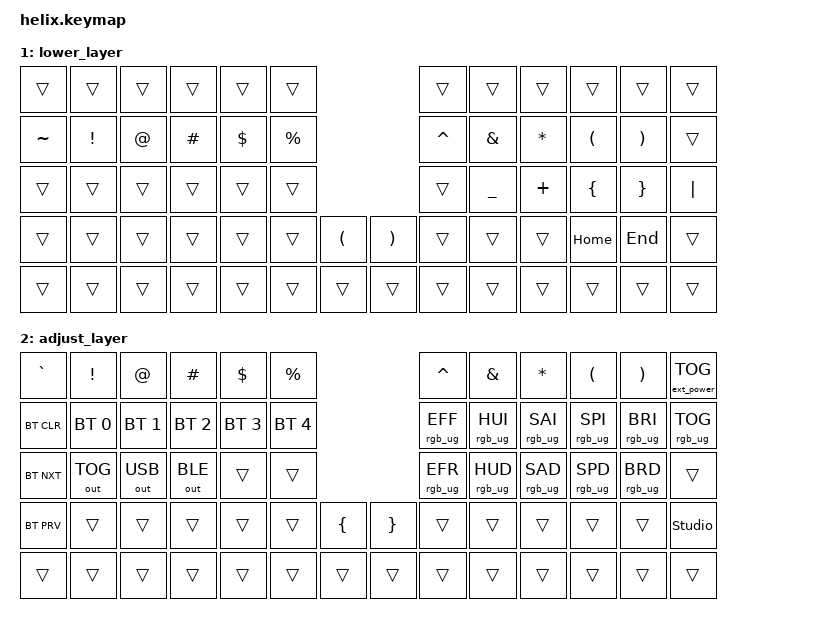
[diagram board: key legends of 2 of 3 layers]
/*
 * Copyright (c) 2020 The ZMK Contributors
 *
 * SPDX-License-Identifier: MIT
 */

 #include <behaviors.dtsi>
 #include <dt-bindings/zmk/keys.h>
 #include <dt-bindings/zmk/bt.h>
 #include <dt-bindings/zmk/rgb.h>
 #include <dt-bindings/zmk/ext_power.h>
 #include <dt-bindings/zmk/outputs.h>

 #define DEFAULT 0
 #define LOWER  1
 #define RAISE  2
 #define ADJUST 3

/* NOTE: At the time of the creation of this keymap, there are no specified codes for 'eisuu' and 'kana' input in ZMK.
However, 'LANG1' and 'LANG2' are fully-functioning candidates for 'kana' and 'eisuu' input respectively.
As such, those are in use within the default layer at this time.*/

/ {
       keymap {
              compatible = "zmk,keymap";
              wakeup-source;

              default_layer {
 // ---------------------------------------------------------------------------------------------------------------------------------
 // | GRAVE  |   1    |   2    |   3    |   4    |   5    |                                      |   6    |   7    |   8    |   9    |   0    |  DEL   |
 // |  TAB   |   Q    |   W    |   E    |   R    |   T    |                                      |   Y    |   U    |   I    |   O    |   P    |  BSPC  |
 // |  CTRL  |   A    |   S    |   D    |   F    |   G    |                                      |   H    |   J    |   K    |   L    |   ;    |   '    |
 // |  SHIFT |   Z    |   X    |   C    |   V    |   B    |  LBKT  |                    |  RBKT  |   N    |   M    |   ,    |   .    |   /    |  RET   |
 // | ADJUST |  ESC   |  ALT   |  LGUI  | EISUU  | LOWER  | SPACE  |                    |  SPACE | RAISE  |  KANA  |  LEFT  |  DOWN  |  UP    |  RIGHT |
                     bindings = <
       &kp GRAVE  &kp N1    &kp N2   &kp N3     &kp N4    &kp N5               
       &kp ESC    &kp Q     &kp W    &kp E      &kp R     &kp T                
       &kp TAB    &kp A     &kp S    &kp D      &kp F     &kp G               
       &kp LSHFT  &kp SLASH &kp Z    &kp X      &kp C     &kp V     &kp B     
       &kp LCTRL  &kp LGUI  &kp LALT &mo ADJUST &kp LOWER &kp SPACE
                     >;
              };
              lower_layer {
 // ---------------------------------------------------------------------------------------------------------------------------------
 // |      |      |      |      |      |      |                                  |      |      |      |      |      |      |
 // |  ~   |  !   |  @   |  #   |  $   |  %   |                                  |  ^   |  &   |  *   |  (   |  )   |      |
 // |      |      |      |      |      |      |                                  |      |  _   |  +   |  {   |  }   | PIPE |
 // |      |      |      |      |      |      |  (   |                    |  )   |      |      |      | HOME | END  |      |
 // |      |      |      |      |      |      |      |                    |      |      |      |      |      |      |      |
                     bindings = <
       &trans    &trans   &trans &trans   &trans   &trans                             &trans    &trans    &trans    &trans   &trans   &trans
       &kp TILDE &kp EXCL &kp AT &kp HASH &kp DLLR &kp PRCNT                          &kp CARET &kp AMPS  &kp ASTRK &kp LPAR &kp RPAR &trans
       &trans    &trans   &trans &trans   &trans   &trans                             &trans    &kp UNDER &kp PLUS  &kp LBRC &kp RBRC &kp PIPE
       &trans    &trans   &trans &trans   &trans   &trans    &kp LPAR        &kp RPAR &trans    &trans    &trans    &kp HOME &kp END  &trans
       &trans    &trans   &trans &trans   &trans   &trans    &trans          &trans   &trans    &trans    &trans    &trans   &trans   &trans
                     >;
              };
              adjust_layer {
 // ---------------------------------------------------------------------------------------------------------------------------------
 // |    `     |    !     |    @     |    #     |    $     |    %     |                                          |    ^     |    &     |    *     |    (     |    )     |  EP TOG  |
 // |  BT CLR  | BT SEL0  | BT SEL1  | BT SEL2  | BGT SEL3 | BT SEL4  |                                          | RGB EFF+ | RGB HUE+ | RGB SAT+ | RGB SPD+ | RGB BRI+ | RGB TOG  |
 // |  BT NXT  | OUT TOG  | OUT USB  | OUT BLE  |          |          |                                          | RGB EFF- | RGB HUE- | RGB SAT- | RGB SPD- | RGB BRI- |          |
 // |  BT PRV  |          |          |          |          |          |    {     |                    |    }     |          |          |          |          |          |          |
 // |          |          |          |          |          |          |          |                    |          |          |          |          |          |          |          |
                     bindings = <
       &kp GRAVE  &kp EXCL     &kp AT       &kp HASH     &kp DLLR     &kp PRCNT                             &kp CARET       &kp AMPS        &kp ASTRK       &kp LPAR        &kp RPAR        &ext_power EP_TOG
       &bt BT_CLR &bt BT_SEL 0 &bt BT_SEL 1 &bt BT_SEL 2 &bt BT_SEL 3 &bt BT_SEL 4                          &rgb_ug RGB_EFF &rgb_ug RGB_HUI &rgb_ug RGB_SAI &rgb_ug RGB_SPI &rgb_ug RGB_BRI &rgb_ug RGB_TOG
       &bt BT_NXT &out OUT_TOG &out OUT_USB &out OUT_BLE &trans       &trans                                &rgb_ug RGB_EFR &rgb_ug RGB_HUD &rgb_ug RGB_SAD &rgb_ug RGB_SPD &rgb_ug RGB_BRD &trans
       &bt BT_PRV &trans       &trans       &trans       &trans       &trans       &kp LBRC        &kp RBRC &trans          &trans          &trans          &trans          &trans          &studio_unlock
       &trans     &trans       &trans       &trans       &trans       &trans       &trans          &trans   &trans          &trans          &trans          &trans          &trans          &trans
                     >;
              };
       };
};
